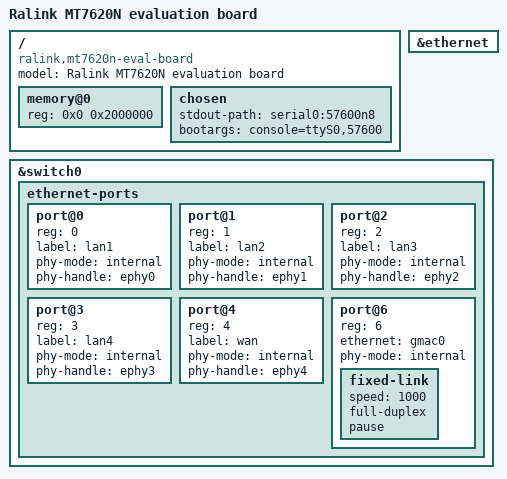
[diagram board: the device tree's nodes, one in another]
// SPDX-License-Identifier: GPL-2.0
/dts-v1/;

#include "mt7620n.dtsi"

/ {
	compatible = "ralink,mt7620n-eval-board", "ralink,mt7620n-soc";
	model = "Ralink MT7620N evaluation board";

	memory@0 {
		device_type = "memory";
		reg = <0x0 0x2000000>;
	};

	chosen {
		stdout-path = "serial0:57600n8";
		bootargs = "console=ttyS0,57600";
	};
};

&ethernet {
	status = "okay";
};

&switch0 {
	status = "okay";

	ethernet-ports {
		#address-cells = <1>;
		#size-cells = <0>;

		port@0 {
			reg = <0>;
			label = "lan1";
			phy-mode = "internal";
			phy-handle = <&ephy0>;
		};

		port@1 {
			reg = <1>;
			label = "lan2";
			phy-mode = "internal";
			phy-handle = <&ephy1>;
		};

		port@2 {
			reg = <2>;
			label = "lan3";
			phy-mode = "internal";
			phy-handle = <&ephy2>;
		};

		port@3 {
			reg = <3>;
			label = "lan4";
			phy-mode = "internal";
			phy-handle = <&ephy3>;
		};

		port@4 {
			reg = <4>;
			label = "wan";
			phy-mode = "internal";
			phy-handle = <&ephy4>;
		};

		port@6 {
			reg = <6>;
			ethernet = <&gmac0>;
			phy-mode = "internal";

			fixed-link {
				speed = <1000>;
				full-duplex;
				pause;
			};
		};
	};
};
